AUTOSAR XML (schema 4-0-3)
package /DataTypes
  integer type Integer: lower-limit=0, upper-limit=65535
  array type ArrayType
    element Element: type=Integer, max-number-of-elements=5
  constant specification InitConstant: value-spec=10
package /Interfaces
  sender receiver interface DataInterface
    data DataElement: type=Integer
    data ArrayDataElement: type=ArrayType
  client server interface CSInterface
    operation Operation1
      arg Arg1: direction=IN, type=Integer
  mode declaration group ModeGroup
    mode Mode1
    mode Mode2
  mode switch interface ModeSwitchInterface
    mode-group:
      mode declaration group prototype ModeGroup: type=ModeGroup
package /Components
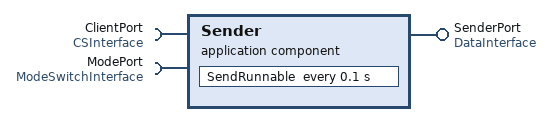
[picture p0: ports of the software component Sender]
  application sw component type Sender  # Sender Component
    provide port SenderPort: provided-interface=DataInterface, provided-com-specs=[{data-element=DataElement, init-value=0}, {data-element=ArrayDataElement, init-value=[1, 2]}]
    require port ClientPort: required-interface=CSInterface, client-server-com-spec=Operation1
    require port ModePort: required-interface=ModeSwitchInterface, required-com-specs=mode-switched-ack=timeout=0.1
    behavior SenderBehavior: port-api-option{port=SenderPort, enable-take-address=false, indirect-api=false}
      runnable SendRunnable: symbol=timing
        data-send-points:
          access SendPoint: accessed-variable=SenderPort.DataElement
        sync call CallPoint1: operation=ClientPort.Operation1
      timing event TimingEvent1: start-on-event=SendRunnable, period=0.1
    service-dependencies:
      service dependency ServiceDep1
    nv block needs NVBlock1: n-data-sets=1
    parameter data prototype Param1: type=Integer
  composition sw component type MyComposition
    component SenderInstance: type=Sender
    component ReceiverInstance: type=Receiver
    connect SenderInstance.SenderPort -> ReceiverInstance.ReceiverPort
    provide port CompSenderPort: provided-interface=DataInterface
package /Implementations
  swc implementation SenderImpl: behavior=SenderBehavior, programming-language=C
package /DataTypeMappings
  data type mapping set DataMapping: data-type-map{application-data-type=Integer, implementation-data-type=Integer}
